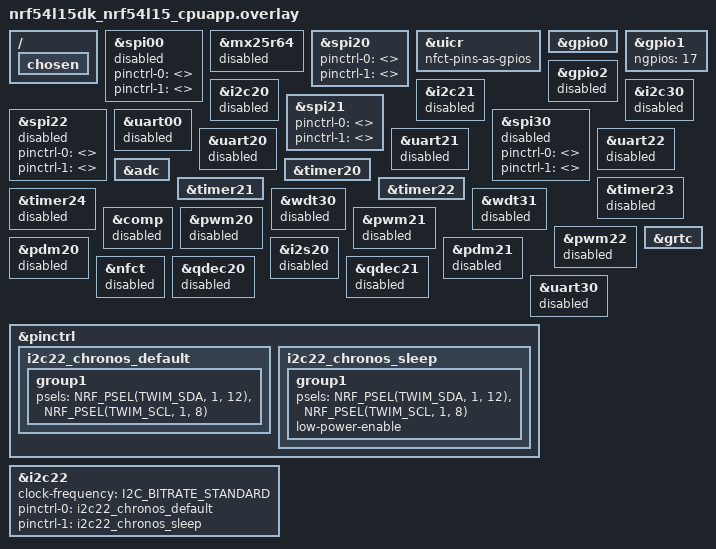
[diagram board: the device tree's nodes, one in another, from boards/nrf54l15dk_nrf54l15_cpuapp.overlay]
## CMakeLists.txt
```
cmake_minimum_required(VERSION 3.20.0)

list(APPEND CONF_FILE ${CMAKE_CURRENT_SOURCE_DIR}/prj.conf)

if(CHRONOS_RELEASE)
	list(APPEND CONF_FILE ${CMAKE_CURRENT_SOURCE_DIR}/prj_release.conf)
endif()

if(CHRONOS_NO_BLE)
	list(APPEND CONF_FILE ${CMAKE_CURRENT_SOURCE_DIR}/prj_no_ble.conf)
endif()

find_package(Zephyr REQUIRED HINTS $ENV{ZEPHYR_BASE})

project(Chronos_nRF54_2)

target_sources(app PRIVATE
  src/main.c
  src/BLE.c
  src/chronos_hfclk.c
  src/data.c
  src/rtc_stim.c
  src/spi.c
  src/stim_nvm.c
  src/timer.c
)

if(CONFIG_BT)
  target_sources(app PRIVATE
    src/ble_session.c
    src/chronos_hw.c
    src/chronos_boot.c
    src/chronos_reed.c
    src/ADC.c
    src/closed_loop.c
    src/cl_algo.c
    src/signal_mv.c
  )
endif()

if(CONFIG_CHRONOS_SYSTEM_OFF)
  target_sources(app PRIVATE src/power_off.c)
endif()

if(CONFIG_CHRONOS_ZMEAS)
  target_sources(app PRIVATE
    src/zmeas_gpio.c
    src/ad5933.c
  )
endif()
```

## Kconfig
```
mainmenu "Chronos"

source "Kconfig.zephyr"

config CHRONOS_ZMEAS
	bool "AD5933 impedance path (Phase A: I2C probe, P0.05 switch GPIO)"
	default y
	depends on I2C
	help
	  Enables I2C22 on P1.08 (SCL) / P1.12 (SDA), P0.05 electrode-route
	  switch GPIO, and boot-time AD5933 register readback.

config CHRONOS_ZMEAS_SWITCH_ACTIVE_HIGH
	bool "Impedance route switch: connect when P0.05 is high"
	default y
	depends on CHRONOS_ZMEAS

config CHRONOS_SYSTEM_OFF
	bool "System OFF sleep with P1.15 reed GPIO wake"
	default y
	depends on BT
	select POWEROFF
	select HWINFO
	select PM_DEVICE
	help
	  After boot or when the BLE session ends, enter System OFF if
	  stimulation is not running. A reed swipe (P1.15 high) wakes the
	  SoC and opens a new BLE session.

config CHRONOS_DEFER_SESSION_HW_INIT
	bool "Defer UART and ZMEAS init until BLE session opens"
	default y
	depends on BT
	help
	  Skips NUS UART and AD5933 boot probe on cold boot before System OFF.
	  Peripherals initialize when the BLE session starts (reed swipe).

config CHRONOS_MINIMAL_BOOT
	bool "Minimal GPIO/reed init before System OFF on cold boot"
	default y
	depends on BT && CHRONOS_SYSTEM_OFF
	help
	  On power-on (not reed GPIO wake), enter System OFF before SPI, timer,
	  and BLE session setup. Reduces time and current before deep sleep.

config CHRONOS_STIM_NVM
	bool "Persist stimulation settings in NVM (Settings/NVS + boot resume)"
	default y
	depends on BT
	help
	  Stores stim parameters and enabled flag in flash with CRC32.
	  When disabled, RAM defaults from config.h apply every boot and
	  boot-time stimulation resume is off (useful for power debugging).

	  When enabled, also set in prj.conf (Settings backend is a Kconfig
	  choice — cannot be auto-selected from here):
	    CONFIG_FLASH_MAP=y
	    CONFIG_FLASH_PAGE_LAYOUT=y
	    CONFIG_NVS=y
	    CONFIG_SETTINGS=y
	    CONFIG_SETTINGS_NVS=y
```

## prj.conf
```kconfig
##############################################################################
# BLE ON/OFF — set to n for RTC-only low-power stim (no radio)
##############################################################################
CONFIG_BT=y
CONFIG_BT_PERIPHERAL=y
CONFIG_BT_DEVICE_NAME="Chronos"
CONFIG_BT_MAX_CONN=1
CONFIG_BT_NUS=y
#CONFIG_BT_NUS_SECURITY_ENABLED=n

##############################################################################
# Peripherals: GPIO, SPIM1, TIMER0 (burst), TIMER2 (period)
##############################################################################
#CONFIG_NRFX=y
CONFIG_DEVICE_DT_METADATA=n
CONFIG_DEVICE_DEPS=n
CONFIG_NRFX_SPIM=y
CONFIG_NRFX_TIMER=y
CONFIG_NRFX_SAADC=y
CONFIG_NRFX_GPPI=y
CONFIG_GPIO=y

##############################################################################
# AD5933 / impedance (Phase A: I2C22 + P0.05 switch GPIO)
##############################################################################
CONFIG_CHRONOS_ZMEAS=y
CONFIG_CHRONOS_ZMEAS_SWITCH_ACTIVE_HIGH=y
CONFIG_I2C=y
#CONFIG_SPI=y
#CONFIG_NRFX_SPIM00=y
CONFIG_NRFX_QSPI=n
# TIMER: nRF54L15 uses TIMER20, TIMER22 etc. (enable per-instance in overlay if needed)
#CONFIG_NRFX_TIMER0=y
#CONFIG_NRFX_TIMER1=y

##############################################################################
# DK LEDs — off on custom (P1.10 = SPI MOSI; no DK LED routing)
##############################################################################
CONFIG_DK_LIBRARY=n

##############################################################################
# Heap / stacks (BLE needs more than RTC-only)
##############################################################################
CONFIG_HEAP_MEM_POOL_SIZE=8192
CONFIG_SYSTEM_WORKQUEUE_STACK_SIZE=2048
CONFIG_MAIN_STACK_SIZE=2048
CONFIG_BT_RX_STACK_SIZE=2048

##############################################################################
# UART / serial (NUS bridge on uart00; console is RTT, not UART)
# NUS sample path expects async UART; enables CONFIG_BT_NUS_UART_* sizes in Kconfig.
##############################################################################
CONFIG_SERIAL=y
CONFIG_UART_ASYNC_API=y

##############################################################################
# Console / log / debug (RTT via J-Link SWD — no UART console on custom board)
##############################################################################
CONFIG_CONSOLE=y
CONFIG_UART_CONSOLE=n
CONFIG_USE_SEGGER_RTT=y
CONFIG_RTT_CONSOLE=y
CONFIG_PRINTK=y
CONFIG_LOG=y
CONFIG_LOG_BACKEND_RTT=y
CONFIG_DEBUG_THREAD_INFO=n
CONFIG_ASSERT=n

##############################################################################
# Boot / size
##############################################################################
CONFIG_BOOT_BANNER=n
CONFIG_NCS_BOOT_BANNER=n
CONFIG_SIZE_OPTIMIZATIONS=y

##############################################################################
# Power management (System OFF, deferred session HW, PM_DEVICE for suspend)
# Note: CONFIG_PM idle is not available on nRF54L15 cpuapp (no HAS_PM).
##############################################################################
CONFIG_CHRONOS_DEFER_SESSION_HW_INIT=y
CONFIG_CHRONOS_MINIMAL_BOOT=y

##############################################################################
# BLE connection interval preference. 15-30 ms instead of 30-50 ms: 25 kHz eCAP
# streaming needs ~50 kB/s, and centrals that cap packets per connection event
# cannot reach that at long intervals. Latency 2 still lets idle links skip events.
##############################################################################
CONFIG_BT_PERIPHERAL_PREF_MIN_INT=12
CONFIG_BT_PERIPHERAL_PREF_MAX_INT=24
CONFIG_BT_PERIPHERAL_PREF_LATENCY=2

##############################################################################
# BLE throughput for 25 kHz ADC streaming (242-byte NUS sample packets).
# 251-byte LL payloads (data length extension, auto-initiated) and a 247-byte
# ATT MTU; 2M PHY is already auto-requested (CONFIG_BT_AUTO_PHY_UPDATE).
# ACL TX count also sizes the ATT and L2CAP TX pools, so more notifications
# can be queued per connection event. The host requires more HCI event
# buffers than ACL TX buffers (one completion event per queued packet).
##############################################################################
CONFIG_BT_BUF_ACL_RX_SIZE=251
CONFIG_BT_BUF_ACL_TX_SIZE=251
CONFIG_BT_CTLR_DATA_LENGTH_MAX=251
CONFIG_BT_L2CAP_TX_MTU=247
CONFIG_BT_BUF_ACL_TX_COUNT=10
CONFIG_BT_BUF_EVT_RX_COUNT=12

##############################################################################
# Release overlay: west build -- -DCHRONOS_RELEASE=1  (disables RTT/log)
# No-BLE A/B: add prj_no_ble.conf in nRF Connect Kconfig fragments, or:
#   west build ... -- -DCHRONOS_NO_BLE=1
##############################################################################

##############################################################################
# Stim NVM — set n to disable flash persistence and boot-time stim resume
# (useful for idle-current debug).
##############################################################################
CONFIG_CHRONOS_SYSTEM_OFF=y
CONFIG_CHRONOS_STIM_NVM=n

##############################################################################
# Flash. When CONFIG_CHRONOS_STIM_NVM=y, also uncomment the block below.
##############################################################################
CONFIG_FLASH=y
CONFIG_SPI_NOR=n
# CONFIG_FLASH_MAP=y
# CONFIG_FLASH_PAGE_LAYOUT=y
# CONFIG_NVS=y
# CONFIG_SETTINGS=y
# CONFIG_SETTINGS_NVS=y
```

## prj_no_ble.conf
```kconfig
##############################################################################
# A/B power test — no BLE / MPSL / SoftDevice (RTC stim path in main.c).
# nRF Connect: Base configuration files = prj.conf, prj_no_ble.conf
# west build ... -- -DCONF_FILE="prj.conf;prj_no_ble.conf"
##############################################################################
CONFIG_BT=n
```

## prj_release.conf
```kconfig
##############################################################################
# Release / field-build overlay — lower idle current (no RTT / log).
# west build -b nrf54l15dk/nrf54l15/cpuapp -- -DCHRONOS_RELEASE=1
##############################################################################
CONFIG_CONSOLE=n
CONFIG_UART_CONSOLE=n
CONFIG_USE_SEGGER_RTT=n
CONFIG_RTT_CONSOLE=n
CONFIG_PRINTK=n
CONFIG_LOG=n
CONFIG_LOG_BACKEND_RTT=n
```

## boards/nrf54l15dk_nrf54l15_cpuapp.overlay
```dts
/*
 * Copyright (c) 2024 Nordic Semiconductor ASA
 *
 * SPDX-License-Identifier: LicenseRef-Nordic-5-Clause
 */
/*
 * nRF54L15 custom / QFN52: SPIM21 nrfx DAC on P1.11 SCK, P1.10 MOSI, P1.09 CS.
 * Analog switches P1.16 / P1.02 / P1.03 (timer.c). UART20 disabled on DK overlay.
 */

/* Disabled: nrfx uses SPIM21; keep mx25r64 disabled to avoid spi00 bus reference. */
&spi00 {
	status = "disabled";
	pinctrl-0 = <>;
	pinctrl-1 = <>;
	pinctrl-names = "default", "sleep";
};
&mx25r64 {
	status = "disabled";
};
/* status = "okay" so SoC domain/clock for SPIM20 is enabled; nrfx drives SPI, no Zephyr SPI driver. */
&spi20 {
	status = "okay";
	pinctrl-0 = <>;
	pinctrl-1 = <>;
	pinctrl-names = "default", "sleep";
};

/* P1.02 (NFC1) and P1.03 (NFC2) analog switches: program UICR on first boot. */
&uicr {
	nfct-pins-as-gpios;
};

&gpio0 {
	status = "okay";
};
&gpio1 {
	status = "okay";
	ngpios = <17>;
};
/* P2 unused on Chronos custom QFN52 — disable port to reduce leakage. */
&gpio2 {
	status = "disabled";
};
/* MBOX (IPC hardware) must be okay for BLE-over-IPC; fixes __device_dts_ord_25 undeclared. */
//&mbox {
	//status = "okay";
//};

/*
 * Power: explicitly disable unused peripherals so they are not initialized
 * (no clocks, no power to those blocks). App uses: uart30, spi20 (nrfx SPIM20), timer00/10 (nrfx), gpio, flash, mbox.
 * nRF54L15 labels: i2c20/21/22/30, spi00/20/21/22/30, uart00/20/21/22/30, timer20/21/22/23/24, etc.
 */
&i2c20 { status = "disabled"; };
&i2c21 { status = "disabled"; };
/* i2c22: AD5933 (SCL P1.08, SDA P1.12). Not i2c21 — same block as nrfx SPIM21. */
&i2c30 { status = "disabled"; };
/* spi00/spi20 cleared above for nrfx; clear pinctrl on rest to avoid device ord refs. */
&spi21 {
	status = "okay";
	pinctrl-0 = <>;
	pinctrl-1 = <>;
	pinctrl-names = "default", "sleep";
};
&spi22 {
	status = "disabled";
	pinctrl-0 = <>;
	pinctrl-1 = <>;
	pinctrl-names = "default", "sleep";
};
&spi30 {
	status = "disabled";
	pinctrl-0 = <>;
	pinctrl-1 = <>;
	pinctrl-names = "default", "sleep";
};
&uart00 { status = "disabled"; };
&uart20 { status = "disabled"; };
&uart21 { status = "disabled"; };
&uart22 { status = "disabled"; };
&adc { status = "okay"; };
&timer20 { status = "okay"; };
&timer21 { status = "okay"; };
&timer22 { status = "okay"; };
&timer23 { status = "disabled"; };
&timer24 { status = "disabled"; };
&wdt30 { status = "disabled"; };
&wdt31 { status = "disabled"; };
&comp { status = "disabled"; };
&pwm20 { status = "disabled"; };
&pwm21 { status = "disabled"; };
&pwm22 { status = "disabled"; };
&pdm20 { status = "disabled"; };
&pdm21 { status = "disabled"; };
&i2s20 { status = "disabled"; };
&nfct { status = "disabled"; };
&qdec20 { status = "disabled"; };
&qdec21 { status = "disabled"; };

/* LFXO: reverted - disabling it increased power on this design. Leave default. */
/* &lfxo { status = "disabled"; }; */
/ {
	chosen {
		/delete-property/ zephyr,console;
		/delete-property/ nordic,nus-uart;
	};
};

/* NUS UART is uart00 (app.overlay). UART30 was DK default — keep disabled. */
&uart30 {
	status = "disabled";
};

&grtc {
    status = "okay";
};

&pinctrl {
	i2c22_chronos_default: i2c22_chronos_default {
		group1 {
			psels = <NRF_PSEL(TWIM_SDA, 1, 12)>,
				<NRF_PSEL(TWIM_SCL, 1, 8)>;
		};
	};

	i2c22_chronos_sleep: i2c22_chronos_sleep {
		group1 {
			psels = <NRF_PSEL(TWIM_SDA, 1, 12)>,
				<NRF_PSEL(TWIM_SCL, 1, 8)>;
			low-power-enable;
		};
	};
};

&i2c22 {
	status = "okay";
	clock-frequency = <I2C_BITRATE_STANDARD>;
	pinctrl-0 = <&i2c22_chronos_default>;
	pinctrl-1 = <&i2c22_chronos_sleep>;
	pinctrl-names = "default", "sleep";
};
```

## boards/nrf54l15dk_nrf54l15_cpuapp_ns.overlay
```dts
/*
 * Copyright (c) 2024 Nordic Semiconductor ASA
 *
 * SPDX-License-Identifier: LicenseRef-Nordic-5-Clause
 */
/*
 * nRF54L15 custom / QFN52: SPIM21 nrfx DAC on P1.11 SCK, P1.10 MOSI, P1.09 CS.
 * Analog switches P1.16 / P1.02 / P1.03 (timer.c).
 */

/* Disabled: nrfx uses SPIM20. Disable mx25r64 to avoid spi00 bus reference. */
&spi00 {
	status = "disabled";
	pinctrl-0 = <>;
	pinctrl-1 = <>;
	pinctrl-names = "default", "sleep";
};
&mx25r64 {
	status = "disabled";
};
/* status = "okay" so SoC domain/clock for SPIM20 is enabled; nrfx drives SPI, no Zephyr SPI driver. */
&spi20 {
	status = "okay";
	pinctrl-0 = <>;
	pinctrl-1 = <>;
	pinctrl-names = "default", "sleep";
};

/* P1.02 (NFC1) and P1.03 (NFC2) analog switches: program UICR on first boot. */
&uicr {
	nfct-pins-as-gpios;
};

&gpio0 {
	status = "okay";
};
&gpio1 {
	status = "okay";
};
&gpio2 {
	status = "okay";
};
/* MBOX (IPC hardware) must be okay for BLE-over-IPC; fixes __device_dts_ord_25 undeclared. */
//&mbox {
	//status = "okay";
//};

/*
 * Power: explicitly disable unused peripherals so they are not initialized
 * (no clocks, no power to those blocks). App uses: uart30, spi20 (nrfx SPIM20), timer00/10 (nrfx), gpio, flash, mbox.
 * nRF54L15 labels: i2c20/21/22/30, spi00/20/21/22/30, uart00/20/21/22/30, timer20/21/22/23/24, etc.
 */
&i2c20 { status = "disabled"; };
&i2c21 { status = "disabled"; };
&i2c22 { status = "disabled"; };
&i2c30 { status = "disabled"; };
/* spi00/spi20 cleared above for nrfx; clear pinctrl on rest to avoid device ord refs. */
&spi21 {
	status = "disabled";
	pinctrl-0 = <>;
	pinctrl-1 = <>;
	pinctrl-names = "default", "sleep";
};
&spi22 {
	status = "disabled";
	pinctrl-0 = <>;
	pinctrl-1 = <>;
	pinctrl-names = "default", "sleep";
};
&spi30 {
	status = "disabled";
	pinctrl-0 = <>;
	pinctrl-1 = <>;
	pinctrl-names = "default", "sleep";
};
&uart00 { status = "disabled"; };
&uart20 { status = "disabled"; };
&uart21 { status = "disabled"; };
&uart22 { status = "disabled"; };
&adc { status = "okay"; };
&timer20 { status = "disabled"; };
&timer21 { status = "okay"; };
&timer22 { status = "okay"; };
&timer23 { status = "disabled"; };
&timer24 { status = "disabled"; };
//&wdt30 { status = "disabled"; };
//&wdt31 { status = "disabled"; };
&comp { status = "disabled"; };
&pwm20 { status = "disabled"; };
&pwm21 { status = "disabled"; };
&pwm22 { status = "disabled"; };
&pdm20 { status = "disabled"; };
&pdm21 { status = "disabled"; };
&i2s20 { status = "disabled"; };
&nfct { status = "disabled"; };
&qdec20 { status = "disabled"; };
&qdec21 { status = "disabled"; };

/* LFXO: reverted - disabling it increased power on this design. Leave default. */
/* &lfxo { status = "disabled"; }; */
/ {
	chosen {
		zephyr,console = &uart30;
		nordic,nus-uart = &uart30;
	};
};

/* nRF54L15 DK uses UART30 for NUS; ensure it is enabled. */
&uart30 {
	status = "okay";
};
&grtc {
    status = "okay";
};
```

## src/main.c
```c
/*
Author: Brandon S Coventry      Wisconsin Institute for Translational Neuroengineering
Date: 2026/02/12 Initialization
Purpose: Chronos firmware ported for the nRF54L15
Revision History: See Github history
Notes:
 - Includes the ability to turn bluetooth transmission on and off in config file. Set CONFIG_BT in config file to 0 to turn off BLE engine
 - Primary stimulation driver is still and interupt based routine. 
*/

/*Basic includes. Minimize to limit current draw from unused engines.*/
//Zephyr includes
#include <zephyr/kernel.h>
#include <zephyr/types.h>
#include <zephyr/irq.h> //Interrupt service routine handlers
#include <zephyr/device.h>  //Must import devicetree files
#include <zephyr/devicetree.h>
#include <soc.h>    //Standard System on chip imports
#include <zephyr/logging/log.h>   //Disable on compile
#include <inttypes.h>

#if defined(CONFIG_BT)
#include <zephyr/bluetooth/bluetooth.h>
#include <zephyr/bluetooth/conn.h>
#endif

//nRFX imports. Note we are primarily runnig
#include <nrfx_spim.h>
#include <nrfx_timer.h>
#include <zephyr/sys/atomic.h>
#include <hal/nrf_gpio.h>
#include <hal/nrf_clock.h>

#if defined(CONFIG_SPI)
#include <zephyr/drivers/spi.h>
#endif

//Chronos engine imports 
#include "BLE.h"  //BLE engine
#include "ble_session.h"
#include "power_off.h"
#include "chronos_hw.h"
#include "chronos_boot.h"
#include "chronos_reed.h"
#include "spi.h" //SPI to howland current source
#include "timer.h"  //Handles interrupt timing of stimulation
#include "rtc_stim.h"   //handles IRQ routines for stimulation
#include "data.h"
#include "config.h"   //Set compilation settings. Look here for CONFIG_BT
#if defined(CONFIG_BT) && !defined(CONFIG_SPI)
#if defined(CONFIG_CHRONOS_STIM_NVM)
#include "stim_nvm.h"
#endif
#endif

#define LOG_MODULE_NAME main
LOG_MODULE_REGISTER(LOG_MODULE_NAME, LOG_LEVEL_INF);

//Add UART Driver only if BLE is active. Note, UART is *virtual*, but still requires pin definitions. 
#if defined(CONFIG_BT)
#include <uart_async_adapter.h>
#include <zephyr/drivers/uart.h>
#include <zephyr/usb/usb_device.h>
#endif

//Set up peripherial initialization
#if defined(CONFIG_BT)
BT_CONN_CB_DEFINE(conn_callbacks) = {
	.connected        = connected,
	.disconnected     = disconnected,
	.recycled         = recycled_cb,
#ifdef CONFIG_BT_NUS_SECURITY_ENABLED
	.security_changed = security_changed,
#endif
};
#endif /* CONFIG_BT */

static void init_pins(void) {
    /* SPI CS and analog-switch GPIO (nrfx SPIM21 + timer.c). */
#if !defined(CONFIG_SPI)
    nrf_gpio_cfg_output(DAC_CS_PIN);
    nrf_gpio_pin_set(DAC_CS_PIN);   /* high (inactive) */
    
#endif

    /*
     * All three analog switches open, matching timer_stim_switches_park(). Levels are driven
     * low before the pins become outputs so there is no glitch on the stimulus path out of
     * reset.
     *
     * Drive is set explicitly rather than via nrf_gpio_cfg_output(): standard (S0S1) slows
     * the edge into the analog switches and reduces charge injection on the electrode path.
     * P1.02 and P1.03 are the NFC pads, whose CPAD_NFC is 5 pF against 1 pF for P1.16, so
     * they inject the most and gain the most from the slower edge. See STIM_SWITCH_HIGH_DRIVE.
     */
    nrf_gpio_port_out_clear(STIM_GPIO_PORT,
                            BIT(SWITCH_PIN_FIRST) | BIT(SWITCH_PIN_INTER) |
                                    BIT(SWITCH_PIN_SECOND));
    {
#if (STIM_SWITCH_HIGH_DRIVE == 1)
	    const nrf_gpio_pin_drive_t drive = NRF_GPIO_PIN_H0H1;
#else
	    const nrf_gpio_pin_drive_t drive = NRF_GPIO_PIN_S0S1;
#endif
	    static const uint32_t switch_pins[] = {
		    NRF_GPIO_PIN_MAP(1, SWITCH_PIN_FIRST),
		    NRF_GPIO_PIN_MAP(1, SWITCH_PIN_INTER),
		    NRF_GPIO_PIN_MAP(1, SWITCH_PIN_SECOND),
	    };
        //nrf_gpio_pin_set(SWITCH_PIN_FIRST);    //*/Brandon remove this before production */
        //nrf_gpio_pin_set(SWITCH_PIN_SECOND);
	    for (size_t i = 0; i < ARRAY_SIZE(switch_pins); i++) {
		    nrf_gpio_cfg(switch_pins[i],
				 NRF_GPIO_PIN_DIR_OUTPUT,
				 NRF_GPIO_PIN_INPUT_DISCONNECT,
				 NRF_GPIO_PIN_NOPULL,
				 drive,
				 NRF_GPIO_PIN_NOSENSE);
	    }
    }

    nrf_gpio_cfg_output(NRF_GPIO_PIN_MAP(STIM_SESSION_GPIO_PORT, STIM_SESSION_GPIO_NUM));
    nrf_gpio_pin_set(NRF_GPIO_PIN_MAP(STIM_SESSION_GPIO_PORT, STIM_SESSION_GPIO_NUM));
}

int main(void)
{
    init_pins();

#if defined(CONFIG_BT)
#if defined(CONFIG_CHRONOS_SYSTEM_OFF) && defined(CONFIG_CHRONOS_MINIMAL_BOOT)
    /*
     * Cold boot: only safe GPIO + reed, then System OFF before SPI/timer/BLE
     * session setup. Reed GPIO wake runs full init below.
     */
    (void)chronos_reed_gpio_init();

    if (!chronos_boot_was_reed_wake()) {
        chronos_power_off_try_enter();
    }
#endif

    chronos_app_init_full();

#if MEASURE_TIMER == 1
    /* measurement_timer_init() is inside chronos_app_init_full when enabled */
#endif
    int err = 0;
    uint32_t experiment_counter = 0;

    if (IS_ENABLED(CONFIG_BT_NUS_SECURITY_ENABLED)) {
        err = bt_conn_auth_cb_register(&conn_auth_callbacks);
        if (err) {
            LOG_ERR("Failed to register authorization callbacks. (err: %d)", err);
            return 0;
        }

        err = bt_conn_auth_info_cb_register(&conn_auth_info_callbacks);
        if (err) {
            LOG_ERR("Failed to register authorization info callbacks. (err: %d)", err);
            return 0;
        }
    }

    ble_session_init();
    LOG_INF("Boot reset cause 0x%08x (RESET_* flags)", chronos_boot_reset_cause());
    LOG_INF("Reed P1.15: swipe to enable BLE; stimulation off until START byte");

#if defined(CONFIG_CHRONOS_SYSTEM_OFF)
    if (!ble_session_is_active()) {
        chronos_power_off_try_enter();
    }
#endif

    for (;;) {
        if (MEASURE_TIMER == 1) {
            k_msleep(10000);
            experiment_counter += 10;
            error_data my_error_data;
            get_error_data(&my_error_data);
            printf("Counter: %i Elapsed: %is\nEvent0 running error: %" PRIu32
                   " avg error: %" PRIu32 " max error: %" PRIu32 "\n"
                   "Events1-3 running error: %" PRIu32 " avg error: %" PRIu32
                   " max error: %" PRIu32 ", %" PRIu32 ", %" PRIu32 "\n",
                   my_error_data.mycounter,
                   experiment_counter,
                   my_error_data.event0_error,
                   (my_error_data.event0_error / my_error_data.mycounter),
                   my_error_data.event0_max,
                   my_error_data.myerror,
                   (my_error_data.myerror / my_error_data.mycounter),
                   my_error_data.event1_max,
                   my_error_data.event2_max,
                   my_error_data.event3_max);
        } else {
            k_sleep(K_FOREVER);
        }
    }
#else
    spi_init();
    timer_burst_init();
    update_pulse_width(CONFIG_PULSE_WIDTH_US);
    update_dac1_amplitude(CONFIG_STIM_AMPLITUDE);
    update_dac2_amplitude(CONFIG_STIM_AMPLITUDE);
    data_init_defaults();

    rtc_stim_start_lfclk();
    rtc_stim_init(CONFIG_STIM_FREQUENCY_HZ);
    LOG_INF("RTC-driven stimulation at %u Hz (no BLE)", CONFIG_STIM_FREQUENCY_HZ);
    for (;;) {
        k_sleep(K_FOREVER);
    }
#endif /* CONFIG_BT */
}

#if defined(CONFIG_BT)
K_THREAD_DEFINE(ble_write_thread_id, STACKSIZE, ble_write_thread, NULL, NULL,
        NULL, PRIORITY, 0, 0);
#endif
```

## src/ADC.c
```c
#include "ADC.h"
#include "BLE.h"
#include "closed_loop.h"

#include <soc.h>
#include <zephyr/kernel.h>
#include <zephyr/logging/log.h>
#include <zephyr/devicetree.h>
#include <nrfx_saadc.h>
#include <nrfx_timer.h>
#include <helpers/nrfx_gppi.h>

LOG_MODULE_REGISTER(chronos_adc, LOG_LEVEL_DBG);

#define SAADC_BUF_POOL_DEPTH 8

struct adc_block {
	int16_t *samples;
	uint16_t seq;
};

static nrfx_timer_t timer_instance = NRFX_TIMER_INSTANCE(TIMER_INSTANCE_NUMBER);
static nrfx_timer_t sample_cnt_timer = NRFX_TIMER_INSTANCE(ADC_SAMPLE_CNT_TIMER);
static nrfx_saadc_channel_t channel1 =
	NRFX_SAADC_DEFAULT_CHANNEL_SE(SAADC_INPUT_PIN1, 0);

static int16_t saadc_sample_buffer[SAADC_BUF_POOL_DEPTH][SAADC_BUFFER_SIZE];
K_MSGQ_DEFINE(adc_sample_msgq, sizeof(struct adc_block), SAADC_BUF_POOL_DEPTH, 4);

static uint16_t saadc_block_seq;
static uint32_t saadc_next_buffer_idx;
static bool adc_hw_running;
static bool recording_stream;
static bool gppi_linked;
static bool sample_cnt_ready;

static nrfx_gppi_handle_t gppi_handle_sample;
static nrfx_gppi_handle_t gppi_handle_start;
static nrfx_gppi_handle_t gppi_handle_count;

static void configure_timer(void);
static void configure_sample_counter(void);
static void configure_saadc(void);
static void configure_ppi(void);
static void adc_hw_start(void);
static void adc_hw_stop(void);

static void saadc_event_handler(nrfx_saadc_evt_t const *p_event)
{
	nrfx_err_t err;

	switch (p_event->type) {
	case NRFX_SAADC_EVT_READY:
		nrfx_timer_enable(&timer_instance);
		break;

	case NRFX_SAADC_EVT_BUF_REQ: {
		uint32_t next = saadc_next_buffer_idx % SAADC_BUF_POOL_DEPTH;

		err = nrfx_saadc_buffer_set(saadc_sample_buffer[next], SAADC_BUFFER_SIZE);
		if (err != 0) {
			LOG_ERR("nrfx_saadc_buffer_set err=%08x", err);
			return;
		}
		saadc_next_buffer_idx++;
		break;
	}

	case NRFX_SAADC_EVT_DONE: {
		struct adc_block blk = {
			.samples = p_event->data.done.p_buffer,
			.seq = saadc_block_seq++,
		};
		int ret = k_msgq_put(&adc_sample_msgq, &blk, K_NO_WAIT);

		if (ret != 0) {
			LOG_WRN("ADC sample queue full");
		}
		break;
	}

	default:
		break;
	}
}

static void adc_consumer_thread(void *a, void *b, void *c)
{
	ARG_UNUSED(a);
	ARG_UNUSED(b);
	ARG_UNUSED(c);

	struct adc_block blk;

	k_sem_take(&ble_init_ok, K_FOREVER);

	while (1) {
		k_msgq_get(&adc_sample_msgq, &blk, K_FOREVER);
		closed_loop_on_saadc_buffer(blk.seq, blk.samples, SAADC_BUFFER_SIZE);
		if (recording_stream || closed_loop_is_active()) {
			(void)ble_send_samples(blk.seq, blk.samples, SAADC_BUFFER_SIZE);
		}
	}
}

K_THREAD_DEFINE(adc_consumer_tid, 2048, adc_consumer_thread, NULL, NULL, NULL, 5, 0, 0);

static void configure_timer(void)
{
	nrfx_err_t err;
	nrfx_timer_config_t timer_config = NRFX_TIMER_DEFAULT_CONFIG(1000000);

	err = nrfx_timer_init(&timer_instance, &timer_config, NULL);
	if (err != 0) {
		LOG_ERR("nrfx_timer_init err=%08x", err);
		return;
	}

	{
		uint32_t timer_ticks = nrfx_timer_us_to_ticks(&timer_instance,
							      SAADC_SAMPLE_INTERVAL_US);

		nrfx_timer_extended_compare(&timer_instance, NRF_TIMER_CC_CHANNEL0, timer_ticks,
					    NRF_TIMER_SHORT_COMPARE0_CLEAR_MASK, false);
	}
}

static void configure_sample_counter(void)
{
	nrfx_err_t err;
	nrfx_timer_config_t cfg = NRFX_TIMER_DEFAULT_CONFIG(1000000);

	cfg.mode = NRF_TIMER_MODE_COUNTER;
	err = nrfx_timer_init(&sample_cnt_timer, &cfg, NULL);
	if (err != 0) {
		LOG_ERR("sample counter init err=%08x", err);
		sample_cnt_ready = false;
		return;
	}
	nrfx_timer_clear(&sample_cnt_timer);
	nrfx_timer_enable(&sample_cnt_timer);
	sample_cnt_ready = true;
}

static void configure_saadc(void)
{
	nrfx_err_t err;

	IRQ_CONNECT(DT_IRQN(DT_NODELABEL(adc)), DT_IRQ(DT_NODELABEL(adc), priority),
		    nrfx_isr, nrfx_saadc_irq_handler, 0);

	err = nrfx_saadc_init(DT_IRQ(DT_NODELABEL(adc), priority));
	if (err != 0) {
		LOG_ERR("nrfx_saadc_init err=%08x", err);
		return;
	}

	channel1.channel_config.gain = NRF_SAADC_GAIN1_4;
	channel1.channel_config.reference = NRF_SAADC_REFERENCE_INTERNAL;
	err = nrfx_saadc_channels_config(&channel1, 1);
	if (err != 0) {
		LOG_ERR("nrfx_saadc_channels_config err=%08x", err);
		return;
	}

	{
		nrfx_saadc_adv_config_t saadc_adv_config = NRFX_SAADC_DEFAULT_ADV_CONFIG;

		err = nrfx_saadc_advanced_mode_set(BIT(0), NRF_SAADC_RESOLUTION_12BIT,
						   &saadc_adv_config, saadc_event_handler);
		if (err != 0) {
			LOG_ERR("nrfx_saadc_advanced_mode_set err=%08x", err);
			return;
		}
	}

	err = nrfx_saadc_buffer_set(saadc_sample_buffer[0], SAADC_BUFFER_SIZE);
	if (err != 0) {
		LOG_ERR("nrfx_saadc_buffer_set err=%08x", err);
		return;
	}
	err = nrfx_saadc_buffer_set(saadc_sample_buffer[1], SAADC_BUFFER_SIZE);
	if (err != 0) {
		LOG_ERR("nrfx_saadc_buffer_set err=%08x", err);
		return;
	}

	saadc_next_buffer_idx = 2U;

	err = nrfx_saadc_mode_trigger();
	if (err != 0) {
		LOG_ERR("nrfx_saadc_mode_trigger err=%08x", err);
	}
}

static void configure_ppi(void)
{
	nrfx_err_t err;

	if (gppi_linked) {
		return;
	}

	err = nrfx_gppi_conn_alloc(
		nrfx_timer_compare_event_address_get(&timer_instance, NRF_TIMER_CC_CHANNEL0),
		nrf_saadc_task_address_get(NRF_SAADC, NRF_SAADC_TASK_SAMPLE),
		&gppi_handle_sample);
	if (err != 0) {
		LOG_ERR("gppi sample alloc err=%08x", err);
		return;
	}

	err = nrfx_gppi_conn_alloc(
		nrf_saadc_event_address_get(NRF_SAADC, NRF_SAADC_EVENT_END),
		nrf_saadc_task_address_get(NRF_SAADC, NRF_SAADC_TASK_START),
		&gppi_handle_start);
	if (err != 0) {
		LOG_ERR("gppi start alloc err=%08x", err);
		return;
	}

	if (sample_cnt_ready) {
		err = nrfx_gppi_conn_alloc(
			nrfx_timer_compare_event_address_get(&timer_instance,
							     NRF_TIMER_CC_CHANNEL0),
			nrfx_timer_task_address_get(&sample_cnt_timer, NRF_TIMER_TASK_COUNT),
			&gppi_handle_count);
		if (err != 0) {
			LOG_ERR("gppi count alloc err=%08x", err);
		}
	}

	nrfx_gppi_conn_enable(gppi_handle_sample);
	nrfx_gppi_conn_enable(gppi_handle_start);
	if (sample_cnt_ready) {
		nrfx_gppi_conn_enable(gppi_handle_count);
	}
	gppi_linked = true;
}

static void adc_hw_start(void)
{
	if (adc_hw_running) {
		return;
	}

	k_msgq_purge(&adc_sample_msgq);
	saadc_block_seq = 0U;
	configure_timer();
	configure_sample_counter();
	configure_saadc();
	configure_ppi();
	adc_hw_running = true;
	LOG_INF("SAADC session started");
}

static void adc_hw_stop(void)
{
	if (!adc_hw_running) {
		return;
	}

	if (gppi_linked && sample_cnt_ready) {
		nrfx_gppi_conn_disable(gppi_handle_count);
	}
	nrfx_timer_disable(&timer_instance);
	nrfx_timer_uninit(&timer_instance);
	if (sample_cnt_ready) {
		nrfx_timer_disable(&sample_cnt_timer);
		nrfx_timer_uninit(&sample_cnt_timer);
		sample_cnt_ready = false;
	}
	nrfx_saadc_uninit();
	saadc_next_buffer_idx = 2U;
	gppi_linked = false;
	adc_hw_running = false;
	LOG_INF("SAADC session stopped");
}

static bool adc_session_needed(void)
{
	return recording_stream || closed_loop_is_active();
}

void adc_init_module(void)
{
	recording_stream = false;
	adc_hw_running = false;
	sample_cnt_ready = false;
}

void adc_set_recording_stream(bool enable)
{
	recording_stream = enable;
}

bool adc_recording_stream_enabled(void)
{
	return recording_stream;
}

void adc_session_refresh(void)
{
	if (adc_session_needed()) {
		if (!adc_hw_running) {
			adc_hw_start();
		}
	} else {
		adc_hw_stop();
	}
}

bool adc_recording_is_active(void)
{
	return adc_hw_running;
}

bool adc_sample_count_get(uint32_t *out)
{
	if (!adc_hw_running || !sample_cnt_ready || out == NULL) {
		return false;
	}

	*out = nrfx_timer_capture(&sample_cnt_timer, NRF_TIMER_CC_CHANNEL0);
	return true;
}
```

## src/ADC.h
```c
#ifndef ADC_H
#define ADC_H

#include <stdbool.h>
#include <stddef.h>
#include <stdint.h>

#include <nrfx_saadc.h>

/* 25 kHz: 2.5x the 10 kHz eCAP front-end bandwidth. */
#define SAADC_SAMPLE_INTERVAL_US 40
/*
 * One buffer is one NUS notification: 2-byte sequence + 120 x int16 = 242 bytes, which needs
 * a negotiated ATT MTU of at least 245. At 25 kHz a buffer completes every 4.8 ms, long enough
 * to ride out the ~1 ms stim burst ISR blocking the SAADC buffer refill.
 */
#define SAADC_BUFFER_SIZE        120
#define SAADC_INPUT_PIN1         NRFX_ANALOG_EXTERNAL_AIN0
#define TIMER_INSTANCE_NUMBER    NRF_TIMER22
#define ADC_SAMPLE_CNT_TIMER     NRF_TIMER21

void adc_init_module(void);
void adc_set_recording_stream(bool enable);
bool adc_recording_stream_enabled(void);
void adc_session_refresh(void);
bool adc_recording_is_active(void);

/** Monotonic sample index since the current ADC session started (PPI-counted). ISR-safe read. */
bool adc_sample_count_get(uint32_t *out);

#endif /* ADC_H */
```

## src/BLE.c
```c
#if defined(CONFIG_BT)
#include <uart_async_adapter.h>
#include <zephyr/drivers/uart.h>
#include <zephyr/usb/usb_device.h>
#if IS_ENABLED(CONFIG_DK_LIBRARY)
#include <dk_buttons_and_leds.h>
#endif
#endif

#include <zephyr/types.h>
#include <zephyr/kernel.h>
#include <zephyr/device.h>
#include <zephyr/devicetree.h>
#include <soc.h>

#if defined(CONFIG_BT)
#include <zephyr/bluetooth/bluetooth.h>
#include <zephyr/bluetooth/uuid.h>
#include <zephyr/bluetooth/gatt.h>
#include <zephyr/bluetooth/hci.h>
#include <bluetooth/services/nus.h>
#include <zephyr/settings/settings.h>
#endif

#include <zephyr/sys/util.h>
#include <zephyr/sys/byteorder.h>
#include <string.h>
#include <errno.h>

#include <zephyr/logging/log.h>
#define LOG_MODULE_NAME peripheral_uart
#include "BLE.h"
#include "ble_session.h"
#include "data.h"
#include "ADC.h"
#include "closed_loop.h"

LOG_MODULE_REGISTER(LOG_MODULE_NAME);
K_SEM_DEFINE(ble_init_ok, 0, 1);

#if defined(CONFIG_BT)
const struct device *uart = DEVICE_DT_GET(DT_CHOSEN(nordic_nus_uart));
struct k_work_delayable uart_work;
static K_FIFO_DEFINE(fifo_uart_tx_data);
static K_FIFO_DEFINE(fifo_uart_rx_data);
#endif

#if defined(CONFIG_BT)
const struct bt_data ad[] = {
	BT_DATA_BYTES(BT_DATA_FLAGS, (BT_LE_AD_GENERAL | BT_LE_AD_NO_BREDR)),
	BT_DATA(BT_DATA_NAME_COMPLETE, DEVICE_NAME, DEVICE_NAME_LEN),
};
const size_t ad_len = ARRAY_SIZE(ad);
const struct bt_data sd[] = {
	BT_DATA_BYTES(BT_DATA_UUID128_ALL, BT_UUID_NUS_VAL),
};
const size_t sd_len = ARRAY_SIZE(sd);
struct k_work adv_work;
struct bt_conn *current_conn;
struct bt_conn *auth_conn;
bool ble_data_ready = false;
#endif

#if defined(CONFIG_BT)
void uart_work_handler(struct k_work *item)
{
	struct uart_data_t *buf;

	buf = k_malloc(sizeof(*buf));
	if (buf) {
		buf->len = 0;
	} else {
		LOG_WRN("Not able to allocate UART receive buffer");
		k_work_reschedule(&uart_work, UART_WAIT_FOR_BUF_DELAY);
		return;
	}

	uart_rx_enable(uart, buf->data, sizeof(buf->data), UART_WAIT_FOR_RX);
}

bool uart_test_async_api(const struct device *dev)
{
#if defined(CONFIG_UART_ASYNC_API)
	const struct uart_driver_api *api =
		(const struct uart_driver_api *)dev->api;

	return (api->callback_set != NULL);
#else
	ARG_UNUSED(dev);
	return false;
#endif
}
#endif

#if defined(CONFIG_BT)
void adv_work_handler(struct k_work *work)
{
	int err = bt_le_adv_start(BT_LE_ADV_CONN_FAST_2, ad, ad_len, sd, sd_len);

	if (err) {
		LOG_ERR("Advertising failed to start (err %d)", err);
		return;
	}

	LOG_INF("Advertising successfully started");
}

void advertising_start(void)
{
	k_work_submit(&adv_work);
}

void connected(struct bt_conn *conn, uint8_t err)
{
	char addr[BT_ADDR_LE_STR_LEN];

	if (err) {
		LOG_ERR("Connection failed, err 0x%02x %s", err, bt_hci_err_to_str(err));
		return;
	}

	bt_addr_le_to_str(bt_conn_get_dst(conn), addr, sizeof(addr));
	LOG_INF("Connected %s", addr);

	current_conn = bt_conn_ref(conn);

#if IS_ENABLED(CONFIG_DK_LIBRARY)
	dk_set_led_on(CON_STATUS_LED);
#endif
}

void disconnected(struct bt_conn *conn, uint8_t reason)
{
	char addr[BT_ADDR_LE_STR_LEN];

	bt_addr_le_to_str(bt_conn_get_dst(conn), addr, sizeof(addr));

	LOG_INF("Disconnected: %s, reason 0x%02x %s", addr, reason, bt_hci_err_to_str(reason));

	if (auth_conn) {
		bt_conn_unref(auth_conn);
		auth_conn = NULL;
	}

	if (current_conn) {
		bt_conn_unref(current_conn);
		current_conn = NULL;
#if IS_ENABLED(CONFIG_DK_LIBRARY)
		dk_set_led_off(CON_STATUS_LED);
#endif
	}

	closed_loop_disarm(CL_EVT_DISCONNECTED);
	adc_set_recording_stream(false);
	adc_session_refresh();
	chronos_stimulation_request_stop();
}

void recycled_cb(void)
{
	LOG_INF("Connection object available from previous conn. Disconnect is complete!");
	advertising_start();
}

#ifdef CONFIG_BT_NUS_SECURITY_ENABLED
void security_changed(struct bt_conn *conn, bt_security_t level,
			     enum bt_security_err err)
{
	char addr[BT_ADDR_LE_STR_LEN];

	bt_addr_le_to_str(bt_conn_get_dst(conn), addr, sizeof(addr));

	if (!err) {
		LOG_INF("Security changed: %s level %u", addr, level);
	} else {
		LOG_WRN("Security failed: %s level %u err %d %s", addr, level, err,
			bt_security_err_to_str(err));
	}
}
#endif /* CONFIG_BT_NUS_SECURITY_ENABLED */

#if defined(CONFIG_BT_NUS_SECURITY_ENABLED)
void auth_passkey_display(struct bt_conn *conn, unsigned int passkey)
{
	char addr[BT_ADDR_LE_STR_LEN];

	bt_addr_le_to_str(bt_conn_get_dst(conn), addr, sizeof(addr));

	LOG_INF("Passkey for %s: %06u", addr, passkey);
}

void auth_passkey_confirm(struct bt_conn *conn, unsigned int passkey)
{
	char addr[BT_ADDR_LE_STR_LEN];

	auth_conn = bt_conn_ref(conn);

	bt_addr_le_to_str(bt_conn_get_dst(conn), addr, sizeof(addr));

	LOG_INF("Passkey for %s: %06u", addr, passkey);

	if (IS_ENABLED(CONFIG_SOC_SERIES_NRF54HX) || IS_ENABLED(CONFIG_SOC_SERIES_NRF54LX)) {
		LOG_INF("Press Button 0 to confirm, Button 1 to reject.");
	} else {
		LOG_INF("Press Button 1 to confirm, Button 2 to reject.");
	}
}


void auth_cancel(struct bt_conn *conn)
{
	char addr[BT_ADDR_LE_STR_LEN];

	bt_addr_le_to_str(bt_conn_get_dst(conn), addr, sizeof(addr));

	LOG_INF("Pairing cancelled: %s", addr);
}


void pairing_complete(struct bt_conn *conn, bool bonded)
{
	char addr[BT_ADDR_LE_STR_LEN];

	bt_addr_le_to_str(bt_conn_get_dst(conn), addr, sizeof(addr));

	LOG_INF("Pairing completed: %s, bonded: %d", addr, bonded);
}


void pairing_failed(struct bt_conn *conn, enum bt_security_err reason)
{
	char addr[BT_ADDR_LE_STR_LEN];

	bt_addr_le_to_str(bt_conn_get_dst(conn), addr, sizeof(addr));

	LOG_INF("Pairing failed conn: %s, reason %d %s", addr, reason,
		bt_security_err_to_str(reason));
}

struct bt_conn_auth_cb conn_auth_callbacks = {
	.passkey_display = auth_passkey_display,
	.passkey_confirm = auth_passkey_confirm,
	.cancel = auth_cancel,
};

struct bt_conn_auth_info_cb conn_auth_info_callbacks = {
	.pairing_complete = pairing_complete,
	.pairing_failed = pairing_failed
};
#else
struct bt_conn_auth_cb conn_auth_callbacks;
struct bt_conn_auth_info_cb conn_auth_info_callbacks;
#endif /* CONFIG_BT_NUS_SECURITY_ENABLED */

#ifdef CONFIG_BT_NUS_SECURITY_ENABLED
void num_comp_reply(bool accept)
{
	if (accept) {
		bt_conn_auth_passkey_confirm(auth_conn);
		LOG_INF("Numeric Match, conn %p", (void *)auth_conn);
	} else {
		bt_conn_auth_cancel(auth_conn);
		LOG_INF("Numeric Reject, conn %p", (void *)auth_conn);
	}

	bt_conn_unref(auth_conn);
	auth_conn = NULL;
}

void button_changed(uint32_t button_state, uint32_t has_changed)
{
	uint32_t buttons = button_state & has_changed;

	if (auth_conn) {
		if (buttons & KEY_PASSKEY_ACCEPT) {
			num_comp_reply(true);
		}

		if (buttons & KEY_PASSKEY_REJECT) {
			num_comp_reply(false);
		}
	}
}
#endif /* CONFIG_BT_NUS_SECURITY_ENABLED */
#endif /* CONFIG_BT */

#if defined(CONFIG_BT)
void configure_gpio(void)
{
	int err;

#if IS_ENABLED(CONFIG_DK_LIBRARY)
#ifdef CONFIG_BT_NUS_SECURITY_ENABLED
	err = dk_buttons_init(button_changed);
	if (err) {
		LOG_ERR("Cannot init buttons (err: %d)", err);
	}
#endif /* CONFIG_BT_NUS_SECURITY_ENABLED */

	err = dk_leds_init();
	if (err) {
		LOG_ERR("Cannot init LEDs (err: %d)", err);
	}
#else
	ARG_UNUSED(err);
#endif
}

void error(void)
{
#if IS_ENABLED(CONFIG_DK_LIBRARY)
	dk_set_leds_state(DK_ALL_LEDS_MSK, DK_NO_LEDS_MSK);
#endif

	while (true) {
		/* Spin for ever */
		k_sleep(K_MSEC(1000));
	}
}
#endif /* CONFIG_BT */

#if defined(CONFIG_BT)
void bt_receive_cb(struct bt_conn *conn, const uint8_t *const data,
			  uint16_t len)
{
	ble_session_feed_activity();

	if (len <= BLE_DATA_BUFFER_SIZE) {
		memcpy(ble_received_data, data, len);
		ble_data_length = len;
		ble_data_ready = true;
	}

	process_received_data(&settings, ble_received_data, ble_data_length);
}

int ble_send_samples(uint16_t seq, const int16_t *samples, size_t count)
{
	static uint8_t pkt[BLE_SAMPLE_PKT_MAX_LEN];
	static bool mtu_warned;
	const size_t len = sizeof(seq) + count * sizeof(int16_t);

	if (samples == NULL || count == 0U || current_conn == NULL || len > sizeof(pkt)) {
		return -EINVAL;
	}

	if (bt_nus_get_mtu(current_conn) < len) {
		if (!mtu_warned) {
			LOG_WRN("NUS MTU %u < sample packet %u; samples not sent",
				(unsigned int)bt_nus_get_mtu(current_conn), (unsigned int)len);
			mtu_warned = true;
		}
		return -EMSGSIZE;
	}

	sys_put_le16(seq, pkt);
	memcpy(pkt + sizeof(seq), samples, count * sizeof(int16_t));

	return bt_nus_send(current_conn, pkt, len);
}

int ble_send_event(const char *msg)
{
	size_t len;

	if (msg == NULL || current_conn == NULL) {
		return -EINVAL;
	}

	len = strlen(msg);
	if (len == 0U) {
		return -EINVAL;
	}

	return bt_nus_send(NULL, (const uint8_t *)msg, len);
}

int ble_send_raw(const uint8_t *data, size_t len)
{
	if (data == NULL || len == 0U || current_conn == NULL) {
		return -EINVAL;
	}

	return bt_nus_send(current_conn, data, len);
}

struct bt_nus_cb nus_cb = {
	.received = bt_receive_cb,
};

void ble_advertising_work_init(void)
{
	k_work_init(&adv_work, adv_work_handler);
}
#endif /* CONFIG_BT */

#if defined(CONFIG_BT)
void uart_cb(const struct device *dev, struct uart_event *evt, void *user_data)
{
	ARG_UNUSED(dev);

	static size_t aborted_len;
	struct uart_data_t *buf;
	static uint8_t *aborted_buf;
	static bool disable_req;

	switch (evt->type) {
	case UART_TX_DONE:
		LOG_DBG("UART_TX_DONE");
		if ((evt->data.tx.len == 0) ||
		    (!evt->data.tx.buf)) {
			return;
		}

		if (aborted_buf) {
			buf = CONTAINER_OF(aborted_buf, struct uart_data_t,
					   data[0]);
			aborted_buf = NULL;
			aborted_len = 0;
		} else {
			buf = CONTAINER_OF(evt->data.tx.buf, struct uart_data_t,
					   data[0]);
		}

		k_free(buf);

		buf = k_fifo_get(&fifo_uart_tx_data, K_NO_WAIT);
		if (!buf) {
			return;
		}

		if (uart_tx(uart, buf->data, buf->len, SYS_FOREVER_MS)) {
			LOG_WRN("Failed to send data over UART");
		}

		break;

	case UART_RX_RDY:
		LOG_DBG("UART_RX_RDY");
		buf = CONTAINER_OF(evt->data.rx.buf, struct uart_data_t, data[0]);
		buf->len += evt->data.rx.len;

		if (disable_req) {
			return;
		}

		if ((evt->data.rx.buf[buf->len - 1] == '\n') ||
		    (evt->data.rx.buf[buf->len - 1] == '\r')) {
			disable_req = true;
			uart_rx_disable(uart);
		}

		break;

	case UART_RX_DISABLED:
		LOG_DBG("UART_RX_DISABLED");
		disable_req = false;

		buf = k_malloc(sizeof(*buf));
		if (buf) {
			buf->len = 0;
		} else {
			LOG_WRN("Not able to allocate UART receive buffer");
			k_work_reschedule(&uart_work, UART_WAIT_FOR_BUF_DELAY);
			return;
		}

		uart_rx_enable(uart, buf->data, sizeof(buf->data),
			       UART_WAIT_FOR_RX);

		break;

	case UART_RX_BUF_REQUEST:
		LOG_DBG("UART_RX_BUF_REQUEST");
		buf = k_malloc(sizeof(*buf));
		if (buf) {
			buf->len = 0;
			uart_rx_buf_rsp(uart, buf->data, sizeof(buf->data));
		} else {
			LOG_WRN("Not able to allocate UART receive buffer");
		}

		break;

	case UART_RX_BUF_RELEASED:
		LOG_DBG("UART_RX_BUF_RELEASED");
		buf = CONTAINER_OF(evt->data.rx_buf.buf, struct uart_data_t,
				   data[0]);

		if (buf->len > 0) {
			k_fifo_put(&fifo_uart_rx_data, buf);
		} else {
			k_free(buf);
		}

		break;

	case UART_TX_ABORTED:
		LOG_DBG("UART_TX_ABORTED");
		if (!aborted_buf) {
			aborted_buf = (uint8_t *)evt->data.tx.buf;
		}

		aborted_len += evt->data.tx.len;
		buf = CONTAINER_OF((void *)aborted_buf, struct uart_data_t,
				   data[0]);

		uart_tx(uart, &buf->data[aborted_len],
			buf->len - aborted_len, SYS_FOREVER_MS);

		break;

	default:
		break;
	}
}
#endif /* CONFIG_BT */

#if defined(CONFIG_BT)
int uart_init(void)
{
	int err;
	int pos;
	struct uart_data_t *rx;
	struct uart_data_t *tx;

	if (!device_is_ready(uart)) {
		return -ENODEV;
	}

	if (IS_ENABLED(CONFIG_USB_DEVICE_STACK)) {
		err = usb_enable(NULL);
		if (err && (err != -EALREADY)) {
			LOG_ERR("Failed to enable USB");
			return err;
		}
	}

	rx = k_malloc(sizeof(*rx));
	if (rx) {
		rx->len = 0;
	} else {
		return -ENOMEM;
	}

	k_work_init_delayable(&uart_work, uart_work_handler);


	if (IS_ENABLED(CONFIG_UART_ASYNC_ADAPTER) && !uart_test_async_api(uart)) {
		/* Implement API adapter */
		uart_async_adapter_init(async_adapter, uart);
		uart = async_adapter;
	}

	err = uart_callback_set(uart, uart_cb, NULL);
	if (err) {
		k_free(rx);
		LOG_ERR("Cannot initialize UART callback");
		return err;
	}

	if (IS_ENABLED(CONFIG_UART_LINE_CTRL)) {
		LOG_INF("Wait for DTR");
		while (true) {
			uint32_t dtr = 0;

			uart_line_ctrl_get(uart, UART_LINE_CTRL_DTR, &dtr);
			if (dtr) {
				break;
			}
			/* Give CPU resources to low priority threads. */
			k_sleep(K_MSEC(100));
		}
		LOG_INF("DTR set");
		err = uart_line_ctrl_set(uart, UART_LINE_CTRL_DCD, 1);
		if (err) {
			LOG_WRN("Failed to set DCD, ret code %d", err);
		}
		err = uart_line_ctrl_set(uart, UART_LINE_CTRL_DSR, 1);
		if (err) {
			LOG_WRN("Failed to set DSR, ret code %d", err);
		}
	}

	tx = k_malloc(sizeof(*tx));

	if (tx) {
		pos = snprintf(tx->data, sizeof(tx->data),
			       "Starting Nordic UART service sample\r\n");

		if ((pos < 0) || (pos >= sizeof(tx->data))) {
			k_free(rx);
			k_free(tx);
			LOG_ERR("snprintf returned %d", pos);
			return -ENOMEM;
		}

		tx->len = pos;
	} else {
		k_free(rx);
		return -ENOMEM;
	}

	err = uart_tx(uart, tx->data, tx->len, SYS_FOREVER_MS);
	if (err) {
		k_free(rx);
		k_free(tx);
		LOG_ERR("Cannot display welcome message (err: %d)", err);
		return err;
	}

	err = uart_rx_enable(uart, rx->data, sizeof(rx->data), UART_WAIT_FOR_RX);
	if (err) {
		LOG_ERR("Cannot enable uart reception (err: %d)", err);
		/* Free the rx buffer only because the tx buffer will be handled in the callback */
		k_free(rx);
	}

	return err;
}
#endif /* CONFIG_BT */

void ble_write_thread(void)
{
#if defined(CONFIG_BT)
	/* Don't go any further until BLE is initialized */
	k_sem_take(&ble_init_ok, K_FOREVER);
	struct uart_data_t nus_data = {
		.len = 0,
	};

	for (;;) {
		/* Wait indefinitely for data to be sent over bluetooth */
		struct uart_data_t *buf = k_fifo_get(&fifo_uart_rx_data,
						     K_FOREVER);

		int plen = MIN(sizeof(nus_data.data) - nus_data.len, buf->len);
		int loc = 0;

		while (plen > 0) {
			memcpy(&nus_data.data[nus_data.len], &buf->data[loc], plen);
			nus_data.len += plen;
			loc += plen;

			if (nus_data.len >= sizeof(nus_data.data) ||
			   (nus_data.data[nus_data.len - 1] == '\n') ||
			   (nus_data.data[nus_data.len - 1] == '\r')) {
				if (bt_nus_send(NULL, nus_data.data, nus_data.len)) {
					LOG_WRN("Failed to send data over BLE connection");
				}
				nus_data.len = 0;
			}

			plen = MIN(sizeof(nus_data.data), buf->len - loc);
		}

		k_free(buf);
	}
#else
	/* BLE disabled: block thread so it never runs */
	k_sem_take(&ble_init_ok, K_FOREVER);
	for (;;) {
		k_sleep(K_FOREVER);
	}
#endif
}
```

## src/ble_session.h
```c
#ifndef BLE_SESSION_H
#define BLE_SESSION_H

#include <stdbool.h>

#if defined(CONFIG_BT)

/** Reed P1.15 (NO, swipe to VCC): each rising edge toggles BLE after lockout (ble_session.c). */
void ble_session_init(void);

/** Reset 5-minute inactivity timeout (call on each NUS RX). */
void ble_session_feed_activity(void);

/** True while BLE session is advertising / stack enabled. */
bool ble_session_is_active(void);

/** Level-high sense on P1.15 for System OFF wake (CONFIG_CHRONOS_SYSTEM_OFF). */
void ble_session_arm_reed_wake_for_system_off(void);

#else

static inline void ble_session_init(void) {}
static inline void ble_session_feed_activity(void) {}
static inline bool ble_session_is_active(void) { return false; }
static inline void ble_session_arm_reed_wake_for_system_off(void) {}

#endif

#endif /* BLE_SESSION_H */
```

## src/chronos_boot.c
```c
/*
 * Full application peripheral init — deferred on cold boot until after System OFF attempt.
 */

#if defined(CONFIG_BT)

#include "chronos_boot.h"
#include "chronos_hw.h"
#include "data.h"
#include "spi.h"
#include "timer.h"
#include "config.h"
#include "ADC.h"
#include "closed_loop.h"

#if !defined(CONFIG_SPI) && defined(CONFIG_CHRONOS_STIM_NVM)
#include "stim_nvm.h"
#endif

#include <zephyr/bluetooth/bluetooth.h>
#include <zephyr/logging/log.h>

LOG_MODULE_REGISTER(chronos_boot, LOG_LEVEL_INF);

void chronos_app_init_full(void)
{
#if defined(CONFIG_SPI)
	k_msleep(10);
#else
	spi_init();
#endif

	timer_init();
	data_init_defaults();
	adc_init_module();
	closed_loop_init();

#if !defined(CONFIG_SPI)
#if defined(CONFIG_CHRONOS_STIM_NVM)
	{
		int nvm_err = stim_nvm_boot_load(&settings, &pending_settings);

		(void)nvm_err;
		update_pulse_width(settings.pulse_width);
		update_stim_frequency(settings.frequency);
		update_dac1_amplitude(settings.DAC_amplitude);
		update_dac2_amplitude(settings.DAC_amplitude);
		if (stim_nvm_wants_boot_resume()) {
			timer_stimulation_enable_from_boot();
		}
	}
#else
	update_pulse_width(settings.pulse_width);
	update_stim_frequency(settings.frequency);
	update_dac1_amplitude(settings.DAC_amplitude);
	update_dac2_amplitude(settings.DAC_amplitude);
#endif
#endif

#if MEASURE_TIMER == 1
	measurement_timer_init();
#endif

#if !defined(CONFIG_CHRONOS_DEFER_SESSION_HW_INIT)
	{
		int err = chronos_session_hw_init();

		if (err != 0) {
			LOG_WRN("Session HW init err %d", err);
		}
	}
#endif
}

#endif /* CONFIG_BT */
```

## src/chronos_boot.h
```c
#ifndef CHRONOS_BOOT_H
#define CHRONOS_BOOT_H

#if defined(CONFIG_BT)

/** SPI, timers, stim defaults, optional session HW (full app init). */
void chronos_app_init_full(void);

#endif

#endif /* CHRONOS_BOOT_H */
```

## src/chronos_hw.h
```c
#ifndef CHRONOS_HW_H
#define CHRONOS_HW_H

#include <stdbool.h>

/** UART (NUS bridge) and optional ZMEAS — deferred until BLE session opens. */
int chronos_session_hw_init(void);

/** Suspend session peripherals when BLE closes (PM device suspend). */
void chronos_session_hw_suspend(void);

bool chronos_session_hw_is_ready(void);

#endif /* CHRONOS_HW_H */
```
